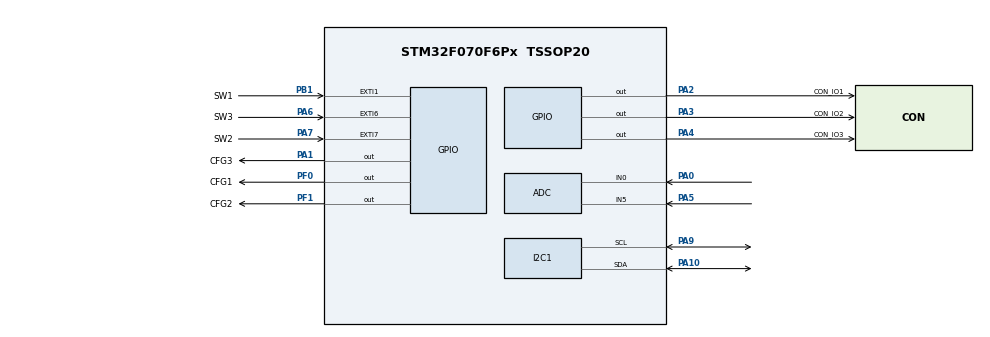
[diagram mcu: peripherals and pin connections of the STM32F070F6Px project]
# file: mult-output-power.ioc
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ADC.ContinuousConvMode=DISABLE
ADC.DiscontinuousConvMode=DISABLE
ADC.DMAContinuousRequests=ENABLE
ADC.SamplingTime=ADC_SAMPLETIME_239CYCLES_5
Mcu.Family=STM32F0
Mcu.Name=STM32F070F6Px
Mcu.Package=TSSOP20
NVIC.EXTI0_1_IRQn=true\:2\:0\:true\:false\:true\:true\:true\:true
NVIC.EXTI4_15_IRQn=true\:2\:0\:true\:false\:true\:true\:true\:true
PA0.Mode=IN0
PA0.Signal=ADC_IN0
PA1.GPIO_Label=CFG3
PA1.Signal=GPIO_Output
PA10.Mode=I2C
PA10.Signal=I2C1_SDA
PA13.Mode=Serial_Wire
PA13.Signal=SYS_SWDIO
PA14.Mode=Serial_Wire
PA14.Signal=SYS_SWCLK
PA2.GPIO_Label=CON_IO1
PA2.PinState=GPIO_PIN_SET
PA2.Signal=GPIO_Output
PA3.GPIO_Label=CON_IO2
PA3.PinState=GPIO_PIN_SET
PA3.Signal=GPIO_Output
PA4.GPIO_Label=CON_IO3
PA4.PinState=GPIO_PIN_SET
PA4.Signal=GPIO_Output
PA5.Mode=IN5
PA5.Signal=ADC_IN5
PA6.GPIO_Label=SW3
PA6.GPIO_ModeDefaultEXTI=GPIO_MODE_IT_FALLING
PA6.GPIO_PuPd=GPIO_PULLUP
PA6.Signal=GPXTI6
PA7.GPIO_Label=SW2
PA7.GPIO_ModeDefaultEXTI=GPIO_MODE_IT_FALLING
PA7.GPIO_PuPd=GPIO_PULLUP
PA7.Signal=GPXTI7
PA9.Mode=I2C
PA9.Signal=I2C1_SCL
PB1.GPIO_Label=SW1
PB1.GPIO_ModeDefaultEXTI=GPIO_MODE_IT_FALLING
PB1.GPIO_PuPd=GPIO_PULLUP
PB1.Signal=GPXTI1
PF0-OSC_IN.GPIO_Label=CFG1
PF0-OSC_IN.PinState=GPIO_PIN_SET
PF0-OSC_IN.Signal=GPIO_Output
PF1-OSC_OUT.GPIO_Label=CFG2
PF1-OSC_OUT.Signal=GPIO_Output
ProjectManager.HeapSize=0x200
ProjectManager.StackSize=0x400
ProjectManager.TargetToolchain=CMake
RCC.AHBFreq_Value=48000000
RCC.APB1Freq_Value=48000000
RCC.APB1TimFreq_Value=48000000
RCC.HCLKFreq_Value=48000000
RCC.PLLMUL=RCC_PLL_MUL6
RCC.SYSCLKFreq_VALUE=48000000
RCC.SYSCLKSource=RCC_SYSCLKSOURCE_PLLCLK
VP_ADC_Vref_Input.Mode=IN-Vrefint
board=custom

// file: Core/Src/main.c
/* USER CODE BEGIN Header */
/**
  ******************************************************************************
  * @file           : main.c
  * @brief          : Main program body
  ******************************************************************************
  * @attention
  *
  * Copyright (c) 2025 STMicroelectronics.
  * All rights reserved.
  *
  * This software is licensed under terms that can be found in the LICENSE file
  * in the root directory of this software component.
  * If no LICENSE file comes with this software, it is provided AS-IS.
  *
  ******************************************************************************
  */
/* USER CODE END Header */
#include "main.h"
#include "adc.h"
#include "i2c.h"
#include "gpio.h"

/* USER CODE BEGIN Includes */
#include "task_app.h"
/* USER CODE END Includes */

void SystemClock_Config(void);

int main(void)
{

  /* MCU Configuration--------------------------------------------------------*/

  /* Reset of all peripherals, Initializes the Flash interface and the Systick. */
  HAL_Init();

  /* Configure the system clock */
  SystemClock_Config();

  /* Initialize all configured peripherals */
  MX_GPIO_Init();
  MX_ADC_Init();
  MX_I2C1_Init();
  /* USER CODE BEGIN 2 */
  init_task();
  /* USER CODE END 2 */

  /* Infinite loop */
  /* USER CODE BEGIN WHILE */
  while (1)
  {
	  task_run();
	  __WFI();
    /* USER CODE END WHILE */

  }
}

void SystemClock_Config(void)
{
  LL_FLASH_SetLatency(LL_FLASH_LATENCY_1);
  while(LL_FLASH_GetLatency() != LL_FLASH_LATENCY_1)
  {
  }
  LL_RCC_HSI_Enable();

   /* Wait till HSI is ready */
  while(LL_RCC_HSI_IsReady() != 1)
  {

  }
  LL_RCC_HSI_SetCalibTrimming(16);
  LL_RCC_HSI14_Enable();

   /* Wait till HSI14 is ready */
  while(LL_RCC_HSI14_IsReady() != 1)
  {

  }
  LL_RCC_HSI14_SetCalibTrimming(16);
  LL_RCC_PLL_ConfigDomain_SYS(LL_RCC_PLLSOURCE_HSI, LL_RCC_PLL_MUL_6, LL_RCC_PREDIV_DIV_1);
  LL_RCC_PLL_Enable();

   /* Wait till PLL is ready */
  while(LL_RCC_PLL_IsReady() != 1)
  {

  }
  LL_RCC_SetAHBPrescaler(LL_RCC_SYSCLK_DIV_1);
  LL_RCC_SetAPB1Prescaler(LL_RCC_APB1_DIV_1);
  LL_RCC_SetSysClkSource(LL_RCC_SYS_CLKSOURCE_PLL);

   /* Wait till System clock is ready */
  while(LL_RCC_GetSysClkSource() != LL_RCC_SYS_CLKSOURCE_STATUS_PLL)
  {

  }
  LL_SetSystemCoreClock(48000000);

   /* Update the time base */
  if (HAL_InitTick (TICK_INT_PRIORITY) != HAL_OK)
  {
    Error_Handler();
  }
  LL_RCC_HSI14_EnableADCControl();
  LL_RCC_SetI2CClockSource(LL_RCC_I2C1_CLKSOURCE_HSI);
}

void Error_Handler(void)
{
  /* USER CODE BEGIN Error_Handler_Debug */
  /* User can add his own implementation to report the HAL error return state */
  task_emergency_shutdown();
  __disable_irq();
  while (1)
  {
  }
  /* USER CODE END Error_Handler_Debug */
}
